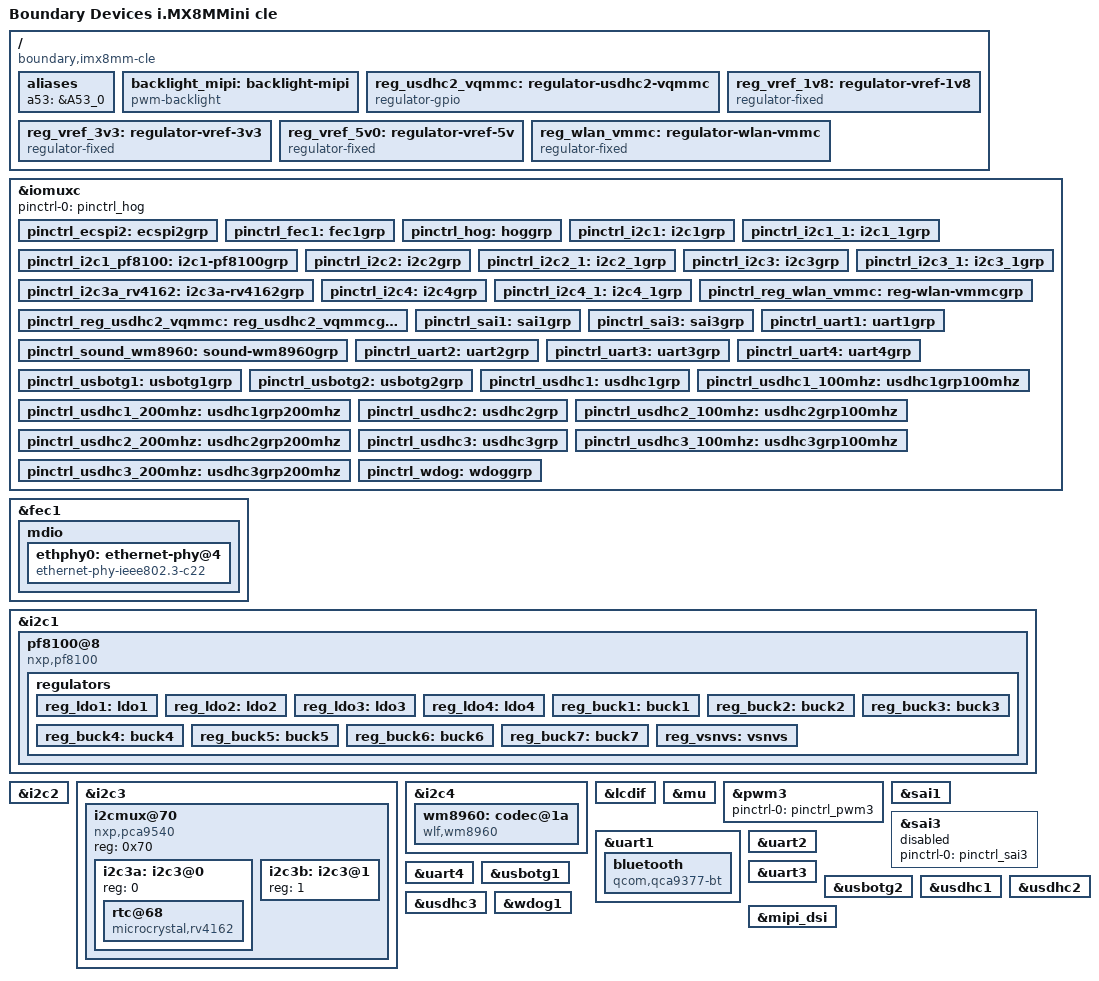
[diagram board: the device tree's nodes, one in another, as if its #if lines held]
// SPDX-License-Identifier: (GPL-2.0+ OR MIT)
/*
 * Copyright 2022 Boundary Devices
 */

/dts-v1/;
#ifdef CONFIG_DEFCONFIG
#define UBOOT
#endif
#define IMX8MM

#define MX8MMN(a, b)	MX8MM_##a b
#define IMX8MMN(a)	IMX8MM_##a
#include "imx8mm.dtsi"

&iomuxc {
	pinctrl-names = "default";
	pinctrl-0 = <&pinctrl_hog>;

	pinctrl_ecspi2: ecspi2grp {
		fsl,pins = <
			/* J15 */
#define GP_ECSPI2_CS0	<&gpio5 13 GPIO_ACTIVE_LOW>
			MX8MMN(IOMUXC_ECSPI2_SS0_GPIO5_IO13, 0x140)	/* Pin 39 */
			MX8MMN(IOMUXC_ECSPI2_MISO_ECSPI2_MISO, 0x14)	/* Pin 41 */
			MX8MMN(IOMUXC_ECSPI2_SCLK_ECSPI2_SCLK, 0x14)	/* Pin 43 */
			MX8MMN(IOMUXC_ECSPI2_MOSI_ECSPI2_MOSI, 0x14)	/* Pin 45 */
		>;
	};

	pinctrl_fec1: fec1grp {
		fsl,pins = <
			/* PAD_CTL_ODE is screwy on 8mm mini, avoid it */
			MX8MMN(IOMUXC_ENET_MDC_ENET1_MDC, 0x00)
			MX8MMN(IOMUXC_ENET_MDIO_ENET1_MDIO, 0x00)
			MX8MMN(IOMUXC_ENET_RD0_ENET1_RGMII_RD0, 0x91)
			MX8MMN(IOMUXC_ENET_RD1_ENET1_RGMII_RD1, 0x91)
			MX8MMN(IOMUXC_ENET_RD2_ENET1_RGMII_RD2, 0x91)
			MX8MMN(IOMUXC_ENET_RD3_ENET1_RGMII_RD3, 0x91)
			MX8MMN(IOMUXC_ENET_RXC_ENET1_RGMII_RXC, 0x91)
			MX8MMN(IOMUXC_ENET_RX_CTL_ENET1_RGMII_RX_CTL, 0x91)
			MX8MMN(IOMUXC_ENET_TD0_ENET1_RGMII_TD0, 0x1f)
			MX8MMN(IOMUXC_ENET_TD1_ENET1_RGMII_TD1, 0x1f)
			MX8MMN(IOMUXC_ENET_TD2_ENET1_RGMII_TD2, 0x1f)
			MX8MMN(IOMUXC_ENET_TD3_ENET1_RGMII_TD3, 0x1f)
			MX8MMN(IOMUXC_ENET_TXC_ENET1_RGMII_TXC, 0x1f)
			MX8MMN(IOMUXC_ENET_TX_CTL_ENET1_RGMII_TX_CTL, 0x1f)
#define GP_FEC1_RESET	<&gpio3 15 GPIO_ACTIVE_LOW>
			MX8MMN(IOMUXC_NAND_RE_B_GPIO3_IO15, 0x100)
#define GPIRQ_FEC1_PHY	<&gpio3 16 IRQ_TYPE_LEVEL_LOW>
			MX8MMN(IOMUXC_NAND_READY_B_GPIO3_IO16, 0x1c0)
		>;
	};

	pinctrl_hog: hoggrp {
		fsl,pins = <
			MX8MMN(IOMUXC_SD2_WP_GPIO2_IO20, 0x140)		/* TP2 */
			MX8MMN(IOMUXC_SD2_RESET_B_GPIO2_IO19, 0x140)	/* TP7 */
			MX8MMN(IOMUXC_SPDIF_TX_GPIO5_IO3, 0x140)	/* TP26 */
			MX8MMN(IOMUXC_GPIO1_IO15_GPIO1_IO15, 0x140)	/* TP27 */
			MX8MMN(IOMUXC_SAI2_TXC_GPIO4_IO25, 0x100)	/* BT_HOST_WAKE */
			MX8MMN(IOMUXC_SAI3_RXC_GPIO4_IO29, 0x100)	/* WL_DEVICE_WAKE */
			MX8MMN(IOMUXC_SAI2_TXD0_GPIO4_IO26, 0x100)	/* BT_UART_WH */
			MX8MMN(IOMUXC_GPIO1_IO11_GPIO1_IO11, 0x140)	/* J15 pin 32 */
			MX8MMN(IOMUXC_GPIO1_IO08_GPIO1_IO8, 0x140)	/* J15 pin 34 */
			MX8MMN(IOMUXC_GPIO1_IO05_GPIO1_IO5, 0x140)	/* J15 pin 36 */
			MX8MMN(IOMUXC_GPIO1_IO03_GPIO1_IO3, 0x140)	/* J15 pin 38 */
		>;
	};

	pinctrl_i2c1: i2c1grp {
		fsl,pins = <
			MX8MMN(IOMUXC_I2C1_SCL_I2C1_SCL, 0x400001c3)
			MX8MMN(IOMUXC_I2C1_SDA_I2C1_SDA, 0x400001c3)
		>;
	};

	pinctrl_i2c1_1: i2c1_1grp {
		fsl,pins = <
#define GP_I2C1_SCL	<&gpio5 14 GPIO_OPEN_DRAIN>
			MX8MMN(IOMUXC_I2C1_SCL_GPIO5_IO14, 0x400001c3)
#define GP_I2C1_SDA	<&gpio5 15 GPIO_OPEN_DRAIN>
			MX8MMN(IOMUXC_I2C1_SDA_GPIO5_IO15, 0x400001c3)
		>;
	};

	pinctrl_i2c1_pf8100: i2c1-pf8100grp {
		fsl,pins = <
#define GP_I2C1_PF8100_EWARN	<&gpio3 3 GPIO_ACTIVE_LOW>
			MX8MMN(IOMUXC_NAND_CE2_B_GPIO3_IO3, 0x1c0)
#define GP_I2C1_PF8100_FAULT	<&gpio3 4 GPIO_ACTIVE_LOW>
			MX8MMN(IOMUXC_NAND_CE3_B_GPIO3_IO4, 0x1c0)
		>;
	};

	pinctrl_i2c2: i2c2grp {
		fsl,pins = <
			MX8MMN(IOMUXC_I2C2_SCL_I2C2_SCL, 0x400001c3)
			MX8MMN(IOMUXC_I2C2_SDA_I2C2_SDA, 0x400001c3)
		>;
	};

	pinctrl_i2c2_1: i2c2_1grp {
		fsl,pins = <
#define GP_I2C2_SCL	<&gpio5 16 GPIO_OPEN_DRAIN>
			MX8MMN(IOMUXC_I2C2_SCL_GPIO5_IO16, 0x400001c3)
#define GP_I2C2_SDA	<&gpio5 17 GPIO_OPEN_DRAIN>
			MX8MMN(IOMUXC_I2C2_SDA_GPIO5_IO17, 0x400001c3)
		>;
	};

	pinctrl_i2c3: i2c3grp {
		fsl,pins = <
			MX8MMN(IOMUXC_I2C3_SCL_I2C3_SCL, 0x400001c3)
			MX8MMN(IOMUXC_I2C3_SDA_I2C3_SDA, 0x400001c3)
		>;
	};

	pinctrl_i2c3_1: i2c3_1grp {
		fsl,pins = <
#define GP_I2C3_SCL	<&gpio5 18 GPIO_OPEN_DRAIN>
			MX8MMN(IOMUXC_I2C3_SCL_GPIO5_IO18, 0x400001c3)
#define GP_I2C3_SDA	<&gpio5 19 GPIO_OPEN_DRAIN>
			MX8MMN(IOMUXC_I2C3_SDA_GPIO5_IO19, 0x400001c3)
		>;
	};

	pinctrl_i2c3a_rv4162: i2c3a-rv4162grp {
		fsl,pins = <
#define GPIRQ_RV4162		<&gpio3 19 IRQ_TYPE_LEVEL_LOW>
			MX8MMN(IOMUXC_SAI5_RXFS_GPIO3_IO19, 0x1c0)
		>;
	};

	pinctrl_i2c4: i2c4grp {
		fsl,pins = <
			MX8MMN(IOMUXC_I2C4_SCL_I2C4_SCL, 0x400001c3)
			MX8MMN(IOMUXC_I2C4_SDA_I2C4_SDA, 0x400001c3)
		>;
	};

	pinctrl_i2c4_1: i2c4_1grp {
		fsl,pins = <
#define GP_I2C4_SCL	<&gpio5 20 GPIO_OPEN_DRAIN>
			MX8MMN(IOMUXC_I2C4_SCL_GPIO5_IO20, 0x400001c3)
#define GP_I2C4_SDA	<&gpio5 21 GPIO_OPEN_DRAIN>
			MX8MMN(IOMUXC_I2C4_SDA_GPIO5_IO21, 0x400001c3)
		>;
	};

	pinctrl_reg_usdhc2_vqmmc: reg_usdhc2_vqmmcgrp {
		fsl,pins = <
#define GP_USDHC2_VSEL	<&gpio3 2 GPIO_ACTIVE_HIGH>
			MX8MMN(IOMUXC_NAND_CE1_B_GPIO3_IO2, 0x100)
		>;
	};

	pinctrl_reg_wlan_vmmc: reg-wlan-vmmcgrp {
		fsl,pins = <
#define GP_REG_WLAN_VMMC	<&gpio5 4 GPIO_ACTIVE_HIGH>
			MX8MMN(IOMUXC_SPDIF_RX_GPIO5_IO4, 0x100)
		>;
	};

	pinctrl_sai1: sai1grp {
		fsl,pins = <
			/* wm8960 */
			MX8MMN(IOMUXC_SAI1_MCLK_SAI1_MCLK, 0xc0)
			MX8MMN(IOMUXC_SAI1_TXFS_SAI1_TX_SYNC, 0xc0)
			MX8MMN(IOMUXC_SAI1_TXC_SAI1_TX_BCLK, 0xc0)
			MX8MMN(IOMUXC_SAI1_TXD0_SAI1_TX_DATA0, 0xc0)
			MX8MMN(IOMUXC_SAI1_RXD0_SAI1_RX_DATA0, 0xc0)
		>;
	};

	pinctrl_sai3: sai3grp {
		fsl,pins = <
			/* BT_PCM */
			MX8MMN(IOMUXC_SAI3_TXFS_SAI3_TX_SYNC, 0xc0)
			MX8MMN(IOMUXC_SAI3_TXC_SAI3_TX_BCLK, 0xc0)
			MX8MMN(IOMUXC_SAI3_TXD_SAI3_TX_DATA0, 0xc0)
			MX8MMN(IOMUXC_SAI3_RXD_SAI3_RX_DATA0, 0xc0)
		>;
	};

	pinctrl_sound_wm8960: sound-wm8960grp {
		fsl,pins = <
#define GP_WM8960_MIC_DET		<&gpio1 10 GPIO_ACTIVE_HIGH>
			MX8MMN(IOMUXC_GPIO1_IO10_GPIO1_IO10, 0x80)
		>;
	};

	pinctrl_uart1: uart1grp {
		fsl,pins = <
			MX8MMN(IOMUXC_SAI2_RXC_UART1_DCE_RX, 0x140)
			MX8MMN(IOMUXC_SAI2_RXFS_UART1_DCE_TX, 0x140)
			MX8MMN(IOMUXC_SAI2_TXFS_UART1_DCE_CTS_B, 0x140)
			MX8MMN(IOMUXC_SAI2_RXD0_UART1_DCE_RTS_B, 0x140)
#define GP_BT_ENABLE	<&gpio3 14 GPIO_ACTIVE_HIGH>
			MX8MMN(IOMUXC_NAND_DQS_GPIO3_IO14, 0x119)
		>;
	};

	pinctrl_uart2: uart2grp {
		fsl,pins = <
			MX8MMN(IOMUXC_UART2_RXD_UART2_DCE_RX, 0x140)
			MX8MMN(IOMUXC_UART2_TXD_UART2_DCE_TX, 0x140)
		>;
	};

	pinctrl_uart3: uart3grp {
		fsl,pins = <
			MX8MMN(IOMUXC_ECSPI1_SCLK_UART3_DCE_RX, 0x140)
			MX8MMN(IOMUXC_ECSPI1_MOSI_UART3_DCE_TX, 0x140)
		>;
	};

	pinctrl_uart4: uart4grp {
		fsl,pins = <
			MX8MMN(IOMUXC_UART4_RXD_UART4_DCE_RX, 0x140)
			MX8MMN(IOMUXC_UART4_TXD_UART4_DCE_TX, 0x140)
		>;
	};

	pinctrl_usbotg1: usbotg1grp {
		fsl,pins = <
			MX8MMN(IOMUXC_GPIO1_IO12_USB1_OTG_PWR, 0x100)
			MX8MMN(IOMUXC_GPIO1_IO13_USB1_OTG_OC, 0x1c0)
		>;
	};

	pinctrl_usbotg2: usbotg2grp {
		fsl,pins = <
#define GP_OTG2_HUB_RESET	<&gpio3 20 GPIO_ACTIVE_LOW>
			MX8MMN(IOMUXC_SAI5_RXC_GPIO3_IO20, 0x100)
		>;
	};

	pinctrl_usdhc1: usdhc1grp {
		fsl,pins = <
			MX8MMN(IOMUXC_SD1_CLK_USDHC1_CLK, 0x190)
			MX8MMN(IOMUXC_SD1_CMD_USDHC1_CMD, 0x1d0)
			MX8MMN(IOMUXC_SD1_DATA0_USDHC1_DATA0, 0x1d0)
			MX8MMN(IOMUXC_SD1_DATA1_USDHC1_DATA1, 0x1d0)
			MX8MMN(IOMUXC_SD1_DATA2_USDHC1_DATA2, 0x1d0)
			MX8MMN(IOMUXC_SD1_DATA3_USDHC1_DATA3, 0x1d0)
			MX8MMN(IOMUXC_SD1_DATA4_USDHC1_DATA4, 0x1d0)
			MX8MMN(IOMUXC_SD1_DATA5_USDHC1_DATA5, 0x1d0)
			MX8MMN(IOMUXC_SD1_DATA6_USDHC1_DATA6, 0x1d0)
			MX8MMN(IOMUXC_SD1_DATA7_USDHC1_DATA7, 0x1d0)
#define GP_EMMC_RESET		<&gpio2 10 GPIO_ACTIVE_LOW>
			MX8MMN(IOMUXC_SD1_RESET_B_GPIO2_IO10, 0x140)
		>;
	};

	pinctrl_usdhc1_100mhz: usdhc1grp100mhz {
		fsl,pins = <
			MX8MMN(IOMUXC_SD1_CLK_USDHC1_CLK, 0x194)
			MX8MMN(IOMUXC_SD1_CMD_USDHC1_CMD, 0x1d4)
			MX8MMN(IOMUXC_SD1_DATA0_USDHC1_DATA0, 0x1d4)
			MX8MMN(IOMUXC_SD1_DATA1_USDHC1_DATA1, 0x1d4)
			MX8MMN(IOMUXC_SD1_DATA2_USDHC1_DATA2, 0x1d4)
			MX8MMN(IOMUXC_SD1_DATA3_USDHC1_DATA3, 0x1d4)
			MX8MMN(IOMUXC_SD1_DATA4_USDHC1_DATA4, 0x1d4)
			MX8MMN(IOMUXC_SD1_DATA5_USDHC1_DATA5, 0x1d4)
			MX8MMN(IOMUXC_SD1_DATA6_USDHC1_DATA6, 0x1d4)
			MX8MMN(IOMUXC_SD1_DATA7_USDHC1_DATA7, 0x1d4)
		>;
	};

	pinctrl_usdhc1_200mhz: usdhc1grp200mhz {
		fsl,pins = <
			MX8MMN(IOMUXC_SD1_CLK_USDHC1_CLK, 0x196)
			MX8MMN(IOMUXC_SD1_CMD_USDHC1_CMD, 0x1d6)
			MX8MMN(IOMUXC_SD1_DATA0_USDHC1_DATA0, 0x1d6)
			MX8MMN(IOMUXC_SD1_DATA1_USDHC1_DATA1, 0x1d6)
			MX8MMN(IOMUXC_SD1_DATA2_USDHC1_DATA2, 0x1d6)
			MX8MMN(IOMUXC_SD1_DATA3_USDHC1_DATA3, 0x1d6)
			MX8MMN(IOMUXC_SD1_DATA4_USDHC1_DATA4, 0x1d6)
			MX8MMN(IOMUXC_SD1_DATA5_USDHC1_DATA5, 0x1d6)
			MX8MMN(IOMUXC_SD1_DATA6_USDHC1_DATA6, 0x1d6)
			MX8MMN(IOMUXC_SD1_DATA7_USDHC1_DATA7, 0x1d6)
		>;
	};

	pinctrl_usdhc2: usdhc2grp {
		fsl,pins = <
			MX8MMN(IOMUXC_SD2_CLK_USDHC2_CLK, 0x190)
			MX8MMN(IOMUXC_SD2_CMD_USDHC2_CMD, 0x1d0)
			MX8MMN(IOMUXC_SD2_DATA0_USDHC2_DATA0, 0x1d0)
			MX8MMN(IOMUXC_SD2_DATA1_USDHC2_DATA1, 0x1d0)
			MX8MMN(IOMUXC_SD2_DATA2_USDHC2_DATA2, 0x1d0)
			MX8MMN(IOMUXC_SD2_DATA3_USDHC2_DATA3, 0x1d0)
#define GP_USDHC2_CD	<&gpio2 12 GPIO_ACTIVE_LOW>
			MX8MMN(IOMUXC_SD2_CD_B_GPIO2_IO12, 0x1c0)
		>;
	};

	pinctrl_usdhc2_100mhz: usdhc2grp100mhz {
		fsl,pins = <
			MX8MMN(IOMUXC_SD2_CLK_USDHC2_CLK, 0x194)
			MX8MMN(IOMUXC_SD2_CMD_USDHC2_CMD, 0x1d4)
			MX8MMN(IOMUXC_SD2_DATA0_USDHC2_DATA0, 0x1d4)
			MX8MMN(IOMUXC_SD2_DATA1_USDHC2_DATA1, 0x1d4)
			MX8MMN(IOMUXC_SD2_DATA2_USDHC2_DATA2, 0x1d4)
			MX8MMN(IOMUXC_SD2_DATA3_USDHC2_DATA3, 0x1d4)
		>;
	};

	pinctrl_usdhc2_200mhz: usdhc2grp200mhz {
		fsl,pins = <
			MX8MMN(IOMUXC_SD2_CLK_USDHC2_CLK, 0x196)
			MX8MMN(IOMUXC_SD2_CMD_USDHC2_CMD, 0x1d6)
			MX8MMN(IOMUXC_SD2_DATA0_USDHC2_DATA0, 0x1d6)
			MX8MMN(IOMUXC_SD2_DATA1_USDHC2_DATA1, 0x1d6)
			MX8MMN(IOMUXC_SD2_DATA2_USDHC2_DATA2, 0x1d6)
			MX8MMN(IOMUXC_SD2_DATA3_USDHC2_DATA3, 0x1d6)
		>;
	};

	pinctrl_usdhc3: usdhc3grp {
		fsl,pins = <
			MX8MMN(IOMUXC_NAND_WE_B_USDHC3_CLK, 0x190)
			MX8MMN(IOMUXC_NAND_WP_B_USDHC3_CMD, 0x1d0)
			MX8MMN(IOMUXC_NAND_DATA04_USDHC3_DATA0, 0x1d0)
			MX8MMN(IOMUXC_NAND_DATA05_USDHC3_DATA1, 0x1d0)
			MX8MMN(IOMUXC_NAND_DATA06_USDHC3_DATA2, 0x1d0)
			MX8MMN(IOMUXC_NAND_DATA07_USDHC3_DATA3, 0x1d0)
			/* Bluetooth slow clock */
			MX8MMN(IOMUXC_GPIO1_IO00_ANAMIX_REF_CLK_32K, 0x03)
			MX8MMN(IOMUXC_SAI3_RXFS_GPIO4_IO28, 0x100)	/* WL_IRQ */
		>;
	};

	pinctrl_usdhc3_100mhz: usdhc3grp100mhz {
		fsl,pins = <
			MX8MMN(IOMUXC_NAND_WE_B_USDHC3_CLK, 0x194)
			MX8MMN(IOMUXC_NAND_WP_B_USDHC3_CMD, 0x1d4)
			MX8MMN(IOMUXC_NAND_DATA04_USDHC3_DATA0, 0x1d4)
			MX8MMN(IOMUXC_NAND_DATA05_USDHC3_DATA1, 0x1d4)
			MX8MMN(IOMUXC_NAND_DATA06_USDHC3_DATA2, 0x1d4)
			MX8MMN(IOMUXC_NAND_DATA07_USDHC3_DATA3, 0x1d4)
		>;
	};

	pinctrl_usdhc3_200mhz: usdhc3grp200mhz {
		fsl,pins = <
			MX8MMN(IOMUXC_NAND_WE_B_USDHC3_CLK, 0x196)
			MX8MMN(IOMUXC_NAND_WP_B_USDHC3_CMD, 0x1d6)
			MX8MMN(IOMUXC_NAND_DATA04_USDHC3_DATA0, 0x1d6)
			MX8MMN(IOMUXC_NAND_DATA05_USDHC3_DATA1, 0x1d6)
			MX8MMN(IOMUXC_NAND_DATA06_USDHC3_DATA2, 0x1d6)
			MX8MMN(IOMUXC_NAND_DATA07_USDHC3_DATA3, 0x1d6)
		>;
	};

	pinctrl_wdog: wdoggrp {
		fsl,pins = <
			MX8MMN(IOMUXC_GPIO1_IO02_WDOG1_WDOG_B, 0x140)
		>;
	};
};

/ {
	model = "Boundary Devices i.MX8MMini cle";
	compatible = "boundary,imx8mm-cle", "fsl,imx8mm";

	aliases {
		a53 = &A53_0;
	};

	backlight_mipi: backlight-mipi {
		brightness-levels = <0 1 2 3 4 5 6 7 8 9 10>;
		compatible = "pwm-backlight";
		default-brightness-level = <8>;
		display = <&display_subsystem>;
		pwms = <&pwm3 0 30000>;		/* 33.3 Khz */
		status = "okay";
	};

	reg_usdhc2_vqmmc: regulator-usdhc2-vqmmc {
		compatible = "regulator-gpio";
		pinctrl-names = "default";
		pinctrl-0 = <&pinctrl_reg_usdhc2_vqmmc>;
		regulator-name = "reg_sd2_vsel";
		regulator-min-microvolt = <1800000>;
		regulator-max-microvolt = <3300000>;
		regulator-type = "voltage";
		regulator-boot-on;
		regulator-always-on;
		gpios = GP_USDHC2_VSEL;
		states = <1800000 0x1
			  3300000 0x0>;
	};

	reg_vref_1v8: regulator-vref-1v8 {
		compatible = "regulator-fixed";
		regulator-name = "vref-1v8";
		regulator-min-microvolt = <1800000>;
		regulator-max-microvolt = <1800000>;
	};

	reg_vref_3v3: regulator-vref-3v3 {
		compatible = "regulator-fixed";
		regulator-name = "vref-3v3";
		regulator-min-microvolt = <3300000>;
		regulator-max-microvolt = <3300000>;
	};

	reg_vref_5v0: regulator-vref-5v {
		compatible = "regulator-fixed";
		regulator-name = "vref-5v";
		regulator-min-microvolt = <5000000>;
		regulator-max-microvolt = <5000000>;
	};

	reg_wlan_vmmc: regulator-wlan-vmmc {
		compatible = "regulator-fixed";
		pinctrl-names = "default";
		pinctrl-0 = <&pinctrl_reg_wlan_vmmc>;
		regulator-name = "reg_wlan_vmmc";
		regulator-min-microvolt = <3300000>;
		regulator-max-microvolt = <3300000>;
		gpio = GP_REG_WLAN_VMMC;
		startup-delay-us = <70000>;
		enable-active-high;
	};

#ifndef UBOOT
	sound-wm8960 {
		audio-codec = <&wm8960>;
		audio-cpu = <&sai1>;
		audio-routing =
			"Ext Spk", "SPK_LP",
			"Ext Spk", "SPK_LN",
			"Ext Spk", "SPK_RP",
			"Ext Spk", "SPK_RN",
			"LINPUT1", "Main MIC",
			"Main MIC", "MICB",
			"RINPUT1", "Mic Jack",
			"Mic Jack", "MICB";
		codec-master;
		compatible = "fsl,imx-audio-wm8960";
		/* Jack is not stuffed */
		mic-det-gpio = GP_WM8960_MIC_DET;
		model = "wm8960-audio";
		pinctrl-names = "default";
		pinctrl-0 = <&pinctrl_sound_wm8960>;
	};
#endif
};

#ifndef UBOOT
&A53_0 {
	arm-supply = <&reg_buck3>;
};

&ecspi2 {
	assigned-clocks = <&clk IMX8MMN(CLK_ECSPI2)>;
	assigned-clock-parents = <&clk IMX8MMN(SYS_PLL1_40M)>;
	assigned-clock-rates = <40000000>;
	cs-gpios = GP_ECSPI2_CS0;
	fsl,spi-num-chipselects = <1>;
	pinctrl-names = "default";
	pinctrl-0 = <&pinctrl_ecspi2>;
	status = "okay";
	#address-cells = <1>;
	#size-cells = <0>;
};
#endif

&fec1 {
	pinctrl-names = "default";
	pinctrl-0 = <&pinctrl_fec1>;
#if 0
	phy-reset-gpios = GP_FEC1_RESET;
#endif
	phy-mode = "rgmii-id";
	phy-handle = <&ethphy0>;
	fsl,magic-packet;
	status = "okay";

	mdio {
		#address-cells = <1>;
		#size-cells = <0>;

		ethphy0: ethernet-phy@4 {
			compatible = "ethernet-phy-ieee802.3-c22";
			reg = <4>;
			interrupts-extended = GPIRQ_FEC1_PHY;
		};
	};
};

#ifndef UBOOT
&gpu {
	status = "okay";
};
#endif

&i2c1 {
	clock-frequency = <400000>;
	pinctrl-names = "default", "gpio";
	pinctrl-0 = <&pinctrl_i2c1>;
	pinctrl-1 = <&pinctrl_i2c1_1>;
	scl-gpios = GP_I2C1_SCL;
	sda-gpios = GP_I2C1_SDA;
	status = "okay";

	pf8100@8 {
		compatible = "nxp,pf8100";
		pinctrl-names = "default";
		pinctrl-0 = <&pinctrl_i2c1_pf8100>;
		reg = <0x08>;

		regulators {
			reg_ldo1: ldo1 {
				regulator-always-on;
				regulator-boot-on;
				regulator-max-microvolt = <5000000>;
				regulator-min-microvolt = <1500000>;
			};

			reg_ldo2: ldo2 {
				regulator-always-on;
				regulator-boot-on;
				regulator-max-microvolt = <5000000>;
				regulator-min-microvolt = <1500000>;
				/* vselect low is 3.3V, high is 1.8V */
				vselect-en;
			};

			reg_ldo3: ldo3 {
				regulator-always-on;
				regulator-boot-on;
				regulator-max-microvolt = <5000000>;
				regulator-min-microvolt = <1500000>;
			};

			reg_ldo4: ldo4 {
				regulator-always-on;
				regulator-boot-on;
				regulator-max-microvolt = <5000000>;
				regulator-min-microvolt = <1500000>;
			};

			reg_buck1: buck1 {
				nxp,phase-shift = <0>;
				regulator-max-microamp = <4500000>;
				regulator-always-on;
				regulator-boot-on;
				regulator-max-microvolt = <1800000>;
				regulator-min-microvolt =  <400000>;
			};

			reg_buck2: buck2 {
				regulator-always-on;
				regulator-boot-on;
				regulator-max-microvolt = <1800000>;
				regulator-min-microvolt =  <400000>;
			};

			reg_buck3: buck3 {
				regulator-always-on;
				regulator-boot-on;
				regulator-max-microvolt = <1800000>;
				regulator-min-microvolt =  <400000>;
				fast-slew = <1>;
			};

			reg_buck4: buck4 {
				regulator-always-on;
				regulator-boot-on;
				regulator-max-microvolt = <1800000>;
				regulator-min-microvolt =  <400000>;
				fast-slew = <1>;
			};

			reg_buck5: buck5 {
				regulator-boot-on;
				regulator-max-microvolt = <1800000>;
				regulator-min-microvolt =  <400000>;
			};

			reg_buck6: buck6 {
				regulator-always-on;
				regulator-boot-on;
				regulator-max-microvolt = <1800000>;
				regulator-min-microvolt =  <400000>;
			};

			reg_buck7: buck7 {
				regulator-always-on;
				regulator-boot-on;
				regulator-max-microvolt = <4100000>;
				regulator-min-microvolt = <1000000>;
			};

			reg_vsnvs: vsnvs {
				regulator-always-on;
				regulator-boot-on;
				regulator-max-microvolt = <3300000>;
				regulator-min-microvolt = <1800000>;
			};
		};
	};
};

&i2c2 {
	clock-frequency = <100000>;
	pinctrl-names = "default", "gpio";
	pinctrl-0 = <&pinctrl_i2c2>;
	pinctrl-1 = <&pinctrl_i2c2_1>;
	scl-gpios = GP_I2C2_SCL;
	sda-gpios = GP_I2C2_SDA;
	status = "okay";
};

&i2c3 {
	clock-frequency = <100000>;
	pinctrl-names = "default", "gpio";
	pinctrl-0 = <&pinctrl_i2c3>;
	pinctrl-1 = <&pinctrl_i2c3_1>;
	scl-gpios = GP_I2C3_SCL;
	sda-gpios = GP_I2C3_SDA;
	status = "okay";

	i2cmux@70 {
		compatible = "nxp,pca9540";
		reg = <0x70>;
		#address-cells = <1>;
		#size-cells = <0>;

		i2c3a: i2c3@0 {
			reg = <0>;
			#address-cells = <1>;
			#size-cells = <0>;
		};

		i2c3b: i2c3@1 {
			reg = <1>;
			#address-cells = <1>;
			#size-cells = <0>;
		};
	};
};

&i2c3a {
	rtc@68 {
		compatible = "microcrystal,rv4162";
		pinctrl-names = "default";
		pinctrl-0 = <&pinctrl_i2c3a_rv4162>;
		reg = <0x68>;
		interrupts-extended = GPIRQ_RV4162;
		wakeup-source;
	};
};

&i2c3b {
};

&i2c4 {
	clock-frequency = <100000>;
	pinctrl-names = "default", "gpio";
	pinctrl-0 = <&pinctrl_i2c4>;
	pinctrl-1 = <&pinctrl_i2c4_1>;
	scl-gpios = GP_I2C4_SCL;
	sda-gpios = GP_I2C4_SDA;
	status = "okay";

	wm8960: codec@1a {
		clock-names = "mclk";
		clocks = <&clk IMX8MMN(CLK_SAI1_ROOT)>;
		compatible = "wlf,wm8960";
		reg = <0x1a>;
		wlf,gpio-cfg = <1 3>;
		wlf,shared-lrclk;
	};
};

&lcdif {
	status = "okay";
};

&mu {
	status = "okay";
};

&pwm3 {
	pinctrl-names = "default";
	pinctrl-0 = <&pinctrl_pwm3>;
	status = "okay";
};

&sai1 {
	assigned-clocks = <&clk IMX8MMN(AUDIO_PLL1)>, <&clk IMX8MMN(AUDIO_PLL2)>, <&clk IMX8MMN(CLK_SAI1)>;
	assigned-clock-parents = <0>, <0>, <&clk IMX8MMN(AUDIO_PLL1_OUT)>;
	assigned-clock-rates = <786432000>, <722534400>, <12288000>;
	pinctrl-names = "default";
	pinctrl-0 = <&pinctrl_sai1>;
	status = "okay";
};

&sai3 {
	pinctrl-names = "default";
	pinctrl-0 = <&pinctrl_sai3>;
	status = "disabled";
};

#ifndef UBOOT
&snvs_pwrkey {
	status = "okay";
};
#endif

&uart1 { /* BT */
	pinctrl-names = "default";
	pinctrl-0 = <&pinctrl_uart1>;
	assigned-clocks = <&clk IMX8MMN(CLK_UART1)>;
	assigned-clock-parents = <&clk IMX8MMN(SYS_PLL1_80M)>;
	uart-has-rtscts;
	status = "okay";

	bluetooth {
		compatible = "qcom,qca9377-bt";
		enable-gpios = GP_BT_ENABLE;
		max-speed = <3000000>;
	};
};

&uart2 { /* console */
	pinctrl-names = "default";
	pinctrl-0 = <&pinctrl_uart2>;
	assigned-clocks = <&clk IMX8MMN(CLK_UART2)>;
	assigned-clock-parents = <&clk IMX8MMN(CLK_24M)>;
	status = "okay";
};

&uart3 { /* J15 */
	pinctrl-names = "default";
	pinctrl-0 = <&pinctrl_uart3>;
	assigned-clocks = <&clk IMX8MMN(CLK_UART3)>;
	assigned-clock-parents = <&clk IMX8MMN(SYS_PLL1_80M)>;
	status = "okay";
};

&uart4 {
	pinctrl-names = "default";
	pinctrl-0 = <&pinctrl_uart4>;
	assigned-clocks = <&clk IMX8MMN(CLK_UART4)>;
	assigned-clock-parents = <&clk IMX8MMN(SYS_PLL1_80M)>;
	status = "okay";
};

&usbotg1 {
	dr_mode = "otg";
	over-current-active-low;
	pinctrl-names = "default";
	pinctrl-0 = <&pinctrl_usbotg1>;
	power-active-high;
	status = "okay";
};

&usbotg2 {
	dr_mode = "host";
	over-current-active-low;
	pinctrl-names = "default";
	pinctrl-0 = <&pinctrl_usbotg2>;
	power-active-high;
	status = "okay";
};

&usdhc1 {
	bus-width = <8>;
	no-mmc-hs400;
	non-removable;
	pinctrl-names = "default", "state_100mhz", "state_200mhz";
	pinctrl-0 = <&pinctrl_usdhc1>;
	pinctrl-1 = <&pinctrl_usdhc1_100mhz>;
	pinctrl-2 = <&pinctrl_usdhc1_200mhz>;
	status = "okay";
	vmmc-supply = <&reg_vref_3v3>;
	vqmmc-1-8-v;
	vqmmc-supply = <&reg_vref_1v8>;
};

&usdhc2 {
	bus-width = <4>;
	cd-gpios = GP_USDHC2_CD;
	pinctrl-names = "default", "state_100mhz", "state_200mhz";
	pinctrl-0 = <&pinctrl_usdhc2>;
	pinctrl-1 = <&pinctrl_usdhc2_100mhz>;
	pinctrl-2 = <&pinctrl_usdhc2_200mhz>;
	status = "okay";
	vqmmc-supply = <&reg_usdhc2_vqmmc>;
};

&usdhc3 {
	bus-width = <4>;
	fsl,sdio-async-interrupt-enabled;
	keep-power-in-suspend;
	no-sd-uhs-sdr104;
	non-removable;
	pinctrl-names = "default", "state_100mhz", "state_200mhz";
	pinctrl-0 = <&pinctrl_usdhc3>;
	pinctrl-1 = <&pinctrl_usdhc3_100mhz>;
	pinctrl-2 = <&pinctrl_usdhc3_200mhz>;
	pm-ignore-notify;
	status = "okay";
	vmmc-supply = <&reg_wlan_vmmc>;
	vqmmc-1-8-v;
	vqmmc-supply = <&reg_vref_1v8>;
};

#ifndef UBOOT
&vpu_g1 {
	status = "okay";
};

&vpu_g2 {
	status = "okay";
};

&vpu_h1 {
	status = "okay";
};

&vpumix_pd {
	dvfs-supply = <&reg_buck5>;
	idle-microvolt = <850000 805000 900000>;
};

&vpu_v4l2 {
	status = "okay";
};
#endif

&wdog1 {
	pinctrl-names = "default";
	pinctrl-0 = <&pinctrl_wdog>;
	fsl,ext-reset-output;
	status = "okay";
};

/* J11 mipi display */
#define MIPI_DSI		mipi_dsi
#define MIPI_DISPLAY		lcdif
#define MIPI_SUBSYSTEM		display_subsystem
#ifndef MIPI_I2C_BUS
#define MIPI_I2C_BUS		i2c2
#endif
#define MIPI_PHY_CLOCK		<&mipi_dsi 0>
#define MIPI_PIXEL_CLOCK	<&clk IMX8MMN(CLK_LCDIF_PIXEL)>

#ifndef MIPI_PWM
#define MIPI_PWM		pwm3
#define GP_MIPI_PWM(a)		<&gpio1 14 a>
#define PD_MIPI_PWM(a)		MX8MMN(IOMUXC_GPIO1_IO14_GPIO1_IO14, a)	/* Pin 7 */
#define PD_MIPI_PWM_OUT(a)	MX8MMN(IOMUXC_GPIO1_IO14_PWM3_OUT, a)
#endif

#define GP_MIPI_IRQ(a)		<&gpio1 1 a>
#define PD_MIPI_IRQ(a)		MX8MMN(IOMUXC_GPIO1_IO01_GPIO1_IO1, a)	/* Pin 8 */

#define GP_MIPI_TS_IRQ(a)	<&gpio1 6 a>
#define PD_MIPI_TS_IRQ(a)	MX8MMN(IOMUXC_GPIO1_IO06_GPIO1_IO6, a)	/* Pin 9 */

#define GP_MIPI_TS_RESET(a)	<&gpio1 7 a>
#define PD_MIPI_TS_RESET(a)	MX8MMN(IOMUXC_GPIO1_IO07_GPIO1_IO7, a)	/* Pin 10 */

#ifndef PD_MIPI_ENABLE
#define GP_MIPI_ENABLE(a)	<&gpio1 9 a>
#define PD_MIPI_ENABLE(a)	MX8MMN(IOMUXC_GPIO1_IO09_GPIO1_IO9, a)	/* Pin 11 */
#endif

#ifdef UBOOT
#include "bd-universal-mipi-dsi.dtsi"
#else
#include "../bd-universal-mipi-dsi.dtsi"
#endif

&mipi_dsi {
	assigned-clocks = <&clk IMX8MMN(CLK_DSI_CORE)>,
			  <&clk IMX8MMN(CLK_DSI_PHY_REF)>,
			  <&clk IMX8MMN(VIDEO_PLL1_REF_SEL)>,
			  <&clk IMX8MMN(CLK_LCDIF_PIXEL)>;
	assigned-clock-parents = <&clk IMX8MMN(SYS_PLL1_266M)>,
				 <&clk IMX8MMN(VIDEO_PLL1_OUT)>,
				 <&clk IMX8MMN(CLK_24M)>;
	assigned-clock-rates = <266000000>, <0>, <0>, <66000000>;
	status = "okay";
};

&mipi_ref2(spi, lcd) {
	assigned-clocks = <&clk IMX8MMN(VIDEO_PLL1)>;
	assigned-clock-rates = <384000000>;
};
